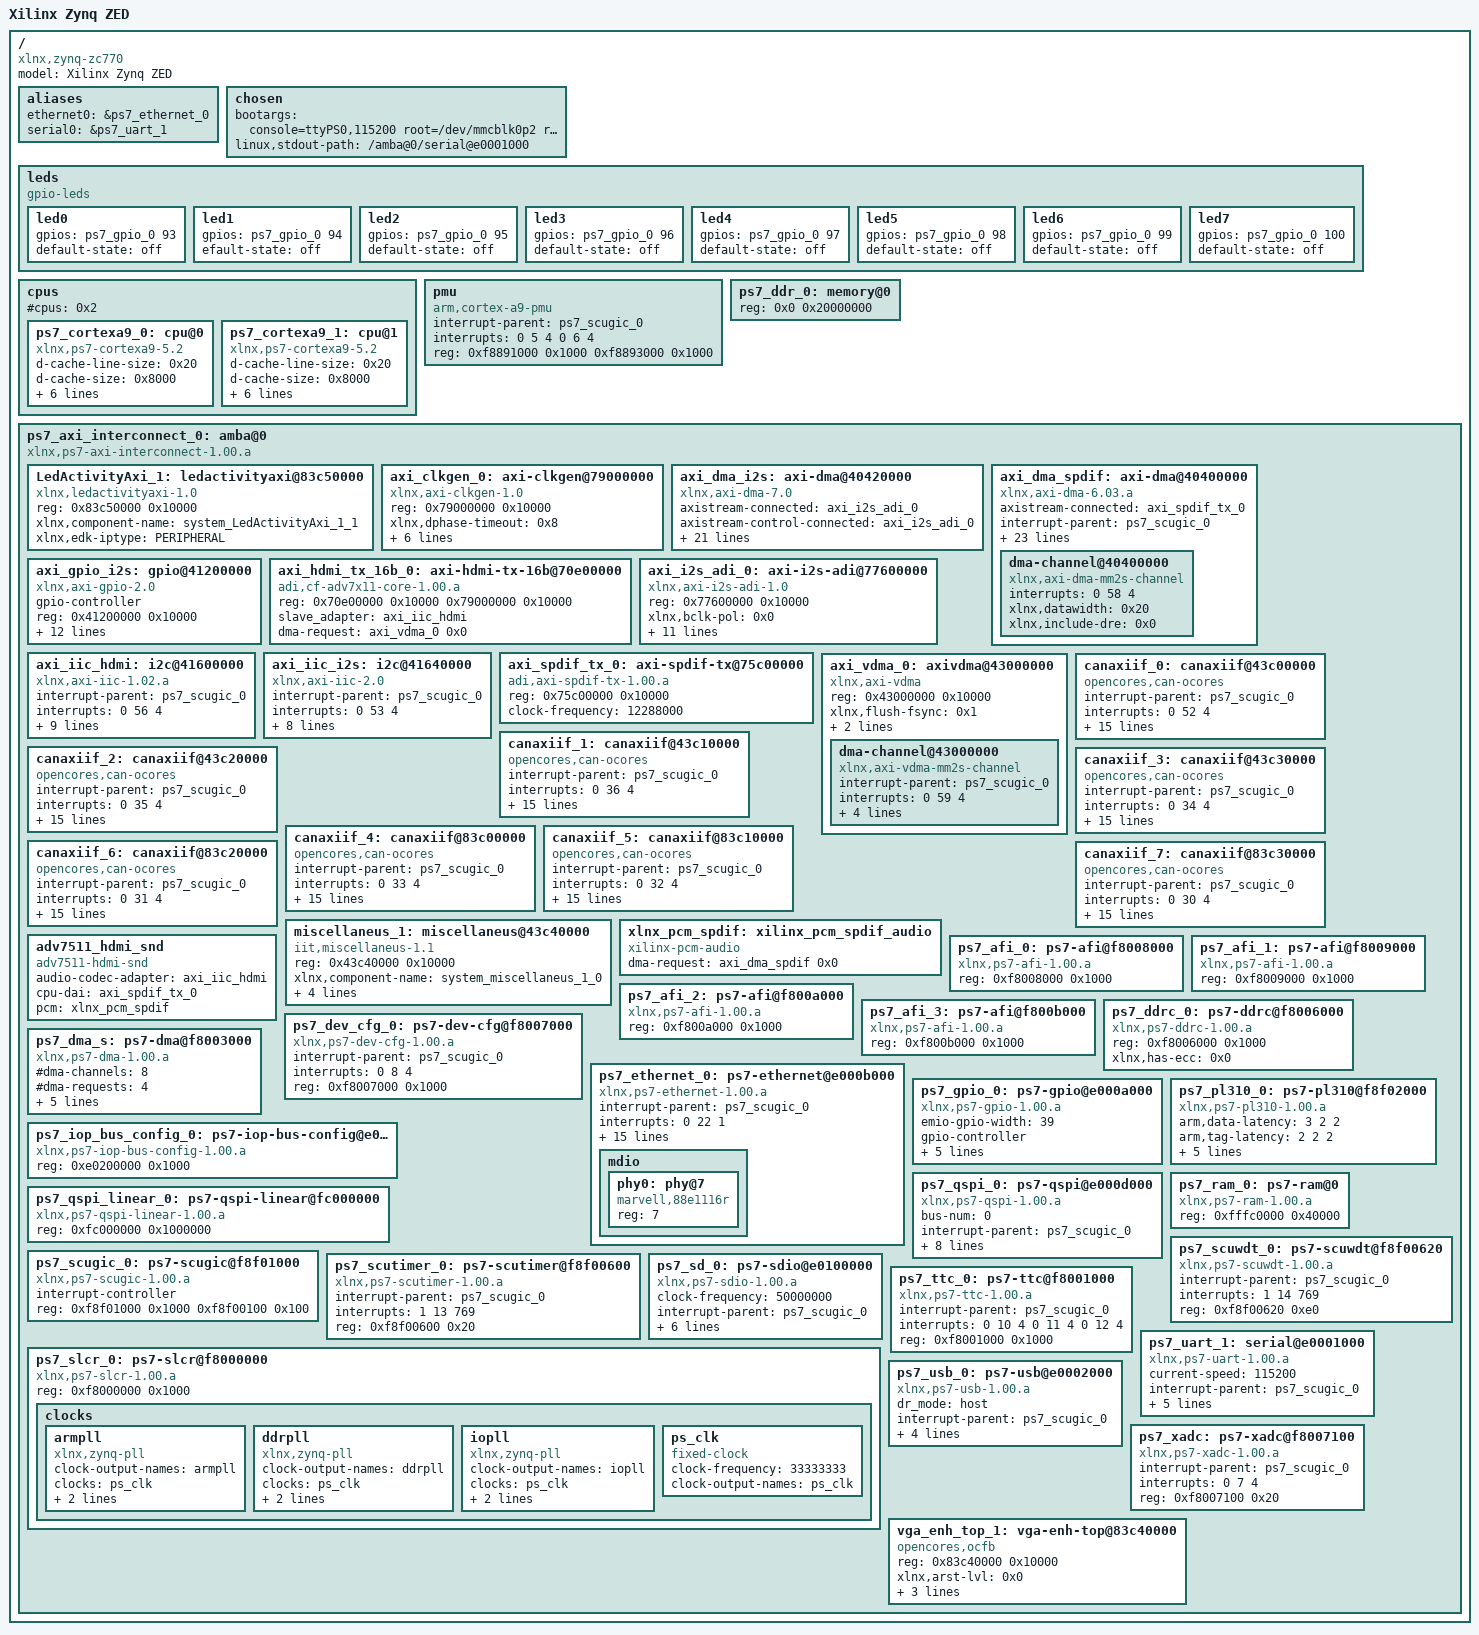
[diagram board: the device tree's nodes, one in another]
/*
 * Device Tree Generator version: 1.1
 *
 * (C) Copyright 2007-2012 Xilinx, Inc.
 * (C) Copyright 2007-2012 Michal Simek
 * (C) Copyright 2007-2012 PetaLogix Qld Pty Ltd
 *
 * Michal SIMEK <monstr@monstr.eu>
 *
 * This program is free software; you can redistribute it and/or
 * modify it under the terms of the GNU General Public License as
 * published by the Free Software Foundation; either version 2 of
 * the License, or (at your option) any later version.
 *
 * This program is distributed in the hope that it will be useful,
 * but WITHOUT ANY WARRANTY; without even the implied warranty of
 * MERCHANTABILITY or FITNESS FOR A PARTICULAR PURPOSE. See the
 * GNU General Public License for more details.
 *
 * You should have received a copy of the GNU General Public License
 * along with this program; if not, write to the Free Software
 * Foundation, Inc., 59 Temple Place, Suite 330, Boston,
 * MA 02111-1307 USA
 *
 * CAUTION: This file is automatically generated by libgen.
 * Version: Xilinx EDK 2013.2 EDK_P.68d
 * Today is: Monday, the 14 of April, 2014; 10:22:48
 *
 * XPS project directory: device-tree_bsp_0
 */

/dts-v1/;
/ {
	#address-cells = <1>;
	#size-cells = <1>;
	compatible = "xlnx,zynq-zc770";
	model = "Xilinx Zynq ZED";

	aliases {
		ethernet0 = &ps7_ethernet_0;
		serial0 = &ps7_uart_1;
	} ;
	chosen {
     /* Booting from SD  */
		bootargs = "console=ttyPS0,115200 root=/dev/mmcblk0p2 rw earlyprintk rootfstype=ext4 rootwait devtmpfs.mount=1 xeno_nucleus.xenomai_gid=1002";
     
     /* Booting from USB 
		bootargs = "console=ttyPS0,115200 root=/dev/sda1 rw earlyprintk rootfstype=ext4 rootwait devtmpfs.mount=1 xeno_nucleus.xenomai_gid=1002";
	  */	
	linux,stdout-path = "/amba@0/serial@e0001000";
	} ;

    leds {
        compatible = "gpio-leds";
        led0 {
            gpios = <&ps7_gpio_0 93 0>;
            default-state = "off";
        };
        led1 {
           gpios = <&ps7_gpio_0 94 0>;
           efault-state = "off";
        };
        led2 {
           gpios = <&ps7_gpio_0 95 0>;
           default-state = "off";
        };
        led3 {
            gpios = <&ps7_gpio_0 96 0>;
            default-state = "off";
        };
        led4 {
           gpios = <&ps7_gpio_0 97 0>;
           default-state = "off";
        };
        led5 {
            gpios = <&ps7_gpio_0 98 0>;
            default-state = "off";
        };
        led6 {
           gpios = <&ps7_gpio_0 99 0>;
           default-state = "off";
        };
        led7 {
           gpios = <&ps7_gpio_0 100 0>;
           default-state = "off";
        };
    };

	cpus {
		#address-cells = <1>;
		#cpus = <0x2>;
		#size-cells = <0>;
		ps7_cortexa9_0: cpu@0 {
			compatible = "xlnx,ps7-cortexa9-5.2";
			d-cache-line-size = <0x20>;
			d-cache-size = <0x8000>;
			device_type = "cpu";
			i-cache-line-size = <0x20>;
			i-cache-size = <0x8000>;
			model = "ps7_cortexa9,5.2";
			reg = <0>;
			xlnx,cpu-1x-clk-freq-hz = <0x69f6bcb>;
			xlnx,cpu-clk-freq-hz = <0x27bc86bf>;
		} ;
		ps7_cortexa9_1: cpu@1 {
			compatible = "xlnx,ps7-cortexa9-5.2";
			d-cache-line-size = <0x20>;
			d-cache-size = <0x8000>;
			device_type = "cpu";
			i-cache-line-size = <0x20>;
			i-cache-size = <0x8000>;
			model = "ps7_cortexa9,5.2";
			reg = <1>;
			xlnx,cpu-1x-clk-freq-hz = <0x69f6bcb>;
			xlnx,cpu-clk-freq-hz = <0x27bc86bf>;
		} ;
	} ;
	pmu {
		compatible = "arm,cortex-a9-pmu";
		interrupt-parent = <&ps7_scugic_0>;
		interrupts = < 0 5 4 0 6 4 >;
		reg = < 0xf8891000 0x1000 0xf8893000 0x1000 >;
	} ;
	ps7_ddr_0: memory@0 {
		device_type = "memory";
		reg = < 0x0 0x20000000 >;
	} ;
	ps7_axi_interconnect_0: amba@0 {
		#address-cells = <1>;
		#size-cells = <1>;
		compatible = "xlnx,ps7-axi-interconnect-1.00.a", "simple-bus";
		ranges ;
		LedActivityAxi_1: ledactivityaxi@83c50000 {
			compatible = "xlnx,ledactivityaxi-1.0";
			reg = < 0x83c50000 0x10000 >;
			xlnx,component-name = "system_LedActivityAxi_1_1";
			xlnx,edk-iptype = "PERIPHERAL";
		} ;
		axi_clkgen_0: axi-clkgen@79000000 {
			compatible = "xlnx,axi-clkgen-1.0";
			reg = < 0x79000000 0x10000 >;
			xlnx,dphase-timeout = <0x8>;
			xlnx,num-mem = <0x1>;
			xlnx,num-reg = <0x1>;
			xlnx,s-axi-min-size = <0x1ff>;
			xlnx,slv-awidth = <0x20>;
			xlnx,slv-dwidth = <0x20>;
			xlnx,use-wstrb = <0x0>;
		} ;
		axi_dma_i2s: axi-dma@40420000 {
			axistream-connected = <&axi_i2s_adi_0>;
			axistream-control-connected = <&axi_i2s_adi_0>;
			compatible = "xlnx,axi-dma-7.0", "xlnx,axi-dma-1.00.a";
			interrupt-parent = <&ps7_scugic_0>;
			interrupts = < 0 55 4 0 54 4 >;
			reg = < 0x40420000 0x10000 >;
			xlnx,dlytmr-resolution = <0x7d>;
			xlnx,enable-multi-channel = <0x0>;
			xlnx,include-mm2s = <0x1>;
			xlnx,include-mm2s-dre = <0x0>;
			xlnx,include-mm2s-sf = <0x1>;
			xlnx,include-s2mm = <0x1>;
			xlnx,include-s2mm-dre = <0x0>;
			xlnx,include-s2mm-sf = <0x1>;
			xlnx,include-sg = <0x1>;
			xlnx,mm2s-burst-size = <0x10>;
			xlnx,num-mm2s-channels = <0x1>;
			xlnx,num-s2mm-channels = <0x1>;
			xlnx,prmry-is-aclk-async = <0x0>;
			xlnx,s2mm-burst-size = <0x10>;
			xlnx,sg-include-desc-queue = <0x1>;
			xlnx,sg-include-stscntrl-strm = <0x0>;
			xlnx,sg-length-width = <0xe>;
			xlnx,sg-use-stsapp-length = <0x0>;
		} ;
		axi_dma_spdif: axi-dma@40400000 {
			#address-cells = <1>;
			#size-cells = <1>;
			#dma-cells = <1>;
			axistream-connected = <&axi_spdif_tx_0>;
			compatible = "xlnx,axi-dma-6.03.a", "xlnx,axi-dma-1.00.a", "xlnx,axi-dma";
			interrupt-parent = <&ps7_scugic_0>;
			interrupts = < 0 58 4 >;
			reg = < 0x40400000 0x10000 >;
			xlnx,sg-include-stscntrl-strm = <0x0>;
			xlnx,dlytmr-resolution = <0x7d>;
			xlnx,enable-multi-channel = <0x0>;
			xlnx,family = "zynq";
			xlnx,generic = <0x0>;
			xlnx,include-mm2s = <0x1>;
			xlnx,include-mm2s-dre = <0x0>;
			xlnx,include-mm2s-sf = <0x1>;
			xlnx,include-s2mm = <0x0>;
			xlnx,include-s2mm-dre = <0x0>;
			xlnx,include-s2mm-sf = <0x1>;
			xlnx,include-sg = <0x1>;
			xlnx,instance = "axi_dma_spdif";
			xlnx,mm2s-burst-size = <0x10>;
			xlnx,num-mm2s-channels = <0x1>;
			xlnx,num-s2mm-channels = <0x1>;
			xlnx,prmry-is-aclk-async = <0x0>;
			xlnx,s2mm-burst-size = <0x10>;
			xlnx,sg-include-desc-queue = <0x0>;
			xlnx,sg-length-width = <0x14>;  
			xlnx,sg-use-stsapp-length = <0x1>;

			dma-channel@40400000 {
				compatible = "xlnx,axi-dma-mm2s-channel";
				interrupts = < 0 58 4 >;
				xlnx,datawidth = <0x20>;
				xlnx,include-dre = <0x0>;
			};
		} ;
		axi_gpio_i2s: gpio@41200000 {
			#gpio-cells = <2>;
			compatible = "xlnx,axi-gpio-2.0", "xlnx,xps-gpio-1.00.a";
			gpio-controller ;
			reg = < 0x41200000 0x10000 >;
			xlnx,all-inputs = <0x0>;
			xlnx,all-inputs-2 = <0x0>;
			xlnx,all-outputs = <0x0>;
			xlnx,all-outputs-2 = <0x0>;
			xlnx,dout-default = <0x0>;
			xlnx,dout-default-2 = <0x0>;
			xlnx,gpio-width = <0x2>;
			xlnx,gpio2-width = <0x20>;
			xlnx,interrupt-present = <0x0>;
			xlnx,is-dual = <0x0>;
			xlnx,tri-default = <0xffffffff>;
			xlnx,tri-default-2 = <0xffffffff>;
		} ;
		axi_hdmi_tx_16b_0: axi-hdmi-tx-16b@70e00000 {
			compatible = "adi,cf-adv7x11-core-1.00.a";
			reg = < 0x70e00000 0x10000 0x79000000 0x10000 >;
			slave_adapter = <&axi_iic_hdmi>;
			dma-request = <&axi_vdma_0 0x0>;
		} ;
		axi_i2s_adi_0: axi-i2s-adi@77600000 {
			compatible = "xlnx,axi-i2s-adi-1.0";
			reg = < 0x77600000 0x10000 >;
			xlnx,bclk-pol = <0x0>;
			xlnx,data-width = <0x18>;
			xlnx,dphase-timeout = <0x8>;
			xlnx,frm-sync = <0x0>;
			xlnx,lrclk-pol = <0x0>;
			xlnx,msb-pos = <0x0>;
			xlnx,num-mem = <0x1>;
			xlnx,num-reg = <0x1>;
			xlnx,s-axi-min-size = <0x1ff>;
			xlnx,slv-awidth = <0x20>;
			xlnx,slv-dwidth = <0x20>;
			xlnx,use-wstrb = <0x0>;
		} ;
		axi_iic_hdmi: i2c@41600000 {
			compatible = "xlnx,axi-iic-1.02.a", "xlnx,xps-iic-2.00.a";
			interrupt-parent = <&ps7_scugic_0>;
			interrupts = < 0 56 4 >;
			reg = < 0x41600000 0x10000 >;
			xlnx,family = "zynq";
			xlnx,gpo-width = <0x1>;
			xlnx,iic-freq = <0x186a0>;
			xlnx,instance = "axi_iic_hdmi";
			xlnx,scl-inertial-delay = <0x0>;
			xlnx,sda-inertial-delay = <0x0>;
			xlnx,sda-level = <0x1>;
			xlnx,ten-bit-adr = <0x0>;
		} ;
		axi_iic_i2s: i2c@41640000 {
			compatible = "xlnx,axi-iic-2.0", "xlnx,xps-iic-2.00.a";
			interrupt-parent = <&ps7_scugic_0>;
			interrupts = < 0 53 4 >;
			reg = < 0x41640000 0x10000 >;
			xlnx,gpo-width = <0x1>;
			xlnx,iic-freq = <0x186a0>;
			xlnx,scl-inertial-delay = <0x0>;
			xlnx,sda-inertial-delay = <0x0>;
			xlnx,sda-level = <0x1>;
			xlnx,smbus-pmbus-host = <0x0>;
			xlnx,ten-bit-adr = <0x0>;
		} ;
		axi_spdif_tx_0: axi-spdif-tx@75c00000 {
			compatible = "adi,axi-spdif-tx-1.00.a";
			reg = < 0x75c00000 0x10000 >;
			clock-frequency = <12288000>;
		} ;
		/* ADV7511 Part (HDMI SPDIF Sound Supported) */
		axi_vdma_0: axivdma@43000000 {
			#address-cells = <1>;
			#size-cells = <1>;
			#dma-cells = <1>;
			compatible = "xlnx,axi-vdma";
			ranges = < 0x43000000 0x43000000 0x10000 >;
			reg = < 0x43000000 0x10000 >;
			xlnx,flush-fsync = <0x1>;
			xlnx,include-sg = <0x0>;
			xlnx,num-fstores = <0x3>;
			dma-channel@43000000 {
				compatible = "xlnx,axi-vdma-mm2s-channel";
				interrupt-parent = <&ps7_scugic_0>;
				interrupts = < 0 59 4 >;
				xlnx,datawidth = <0x40>;
				xlnx,device-id = <0x0>;
				xlnx,genlock-mode = <0x0>;
				xlnx,include-dre = <0x0>;
			} ;
		} ;
		
		canaxiif_0: canaxiif@43c00000 {
			compatible = "opencores,can-ocores";
			interrupt-parent = <&ps7_scugic_0>;
			interrupts = < 0 52 4 >;
			reg = < 0x43c00000 0x10000 >;
			xlnx,component-name = "system_canaxiif_1_1";
			xlnx,dphase-timeout = <0x30>;
			xlnx,edk-iptype = "PERIPHERAL";
			xlnx,family = "virtex6";
			xlnx,interrupt-present = <0x1>;
			xlnx,num-mem = <0x1>;
			xlnx,num-reg = <0x1>;
			xlnx,s-axi-min-size = <0x1ff>;
			xlnx,slv-awidth = <0x20>;
			xlnx,slv-dwidth = <0x20>;
			xlnx,use-wstrb = <0x0>;
            iit_ledctrl = <0x83c50000>;
            iit_resetctrl = <0x43c40000>;
            iit_ordnum = <0x0>;
		} ;
		canaxiif_1: canaxiif@43c10000 {
			compatible = "opencores,can-ocores";
			interrupt-parent = <&ps7_scugic_0>;
			interrupts = < 0 36 4 >;
			reg = < 0x43c10000 0x10000 >;
			xlnx,component-name = "system_canaxiif_0_4";
			xlnx,dphase-timeout = <0x30>;
			xlnx,edk-iptype = "PERIPHERAL";
			xlnx,family = "virtex6";
			xlnx,interrupt-present = <0x1>;
			xlnx,num-mem = <0x1>;
			xlnx,num-reg = <0x1>;
			xlnx,s-axi-min-size = <0x1ff>;
			xlnx,slv-awidth = <0x20>;
			xlnx,slv-dwidth = <0x20>;
			xlnx,use-wstrb = <0x0>;
            iit_ledctrl = <0x83c50000>;
            iit_resetctrl = <0x43c40000>;
            iit_ordnum = <0x1>;
		} ;
		canaxiif_2: canaxiif@43c20000 {
			compatible = "opencores,can-ocores";
			interrupt-parent = <&ps7_scugic_0>;
			interrupts = < 0 35 4 >;
			reg = < 0x43c20000 0x10000 >;
			xlnx,component-name = "system_canaxiif_1_5";
			xlnx,dphase-timeout = <0x30>;
			xlnx,edk-iptype = "PERIPHERAL";
			xlnx,family = "virtex6";
			xlnx,interrupt-present = <0x1>;
			xlnx,num-mem = <0x1>;
			xlnx,num-reg = <0x1>;
			xlnx,s-axi-min-size = <0x1ff>;
			xlnx,slv-awidth = <0x20>;
			xlnx,slv-dwidth = <0x20>;
			xlnx,use-wstrb = <0x0>;
            iit_ledctrl = <0x83c50000>;
            iit_resetctrl = <0x43c40000>;
            iit_ordnum = <0x2>;
		} ;
		canaxiif_3: canaxiif@43c30000 {
			compatible = "opencores,can-ocores";
			interrupt-parent = <&ps7_scugic_0>;
			interrupts = < 0 34 4 >;
			reg = < 0x43c30000 0x10000 >;
			xlnx,component-name = "system_canaxiif_2_6";
			xlnx,dphase-timeout = <0x30>;
			xlnx,edk-iptype = "PERIPHERAL";
			xlnx,family = "virtex6";
			xlnx,interrupt-present = <0x1>;
			xlnx,num-mem = <0x1>;
			xlnx,num-reg = <0x1>;
			xlnx,s-axi-min-size = <0x1ff>;
			xlnx,slv-awidth = <0x20>;
			xlnx,slv-dwidth = <0x20>;
			xlnx,use-wstrb = <0x0>;
            iit_ledctrl = <0x83c50000>;
            iit_resetctrl = <0x43c40000>;
            iit_ordnum = <0x3>;
		} ;
		canaxiif_4: canaxiif@83c00000 {
			compatible = "opencores,can-ocores";
			interrupt-parent = <&ps7_scugic_0>;
			interrupts = < 0 33 4 >;
			reg = < 0x83c00000 0x10000 >;
			xlnx,component-name = "system_canaxiif_3_7";
			xlnx,dphase-timeout = <0x30>;
			xlnx,edk-iptype = "PERIPHERAL";
			xlnx,family = "virtex6";
			xlnx,interrupt-present = <0x1>;
			xlnx,num-mem = <0x1>;
			xlnx,num-reg = <0x1>;
			xlnx,s-axi-min-size = <0x1ff>;
			xlnx,slv-awidth = <0x20>;
			xlnx,slv-dwidth = <0x20>;
			xlnx,use-wstrb = <0x0>;
            iit_ledctrl = <0x83c50000>;
            iit_resetctrl = <0x43c40000>;
            iit_ordnum = <0x4>;
		} ;
		canaxiif_5: canaxiif@83c10000 {
			compatible = "opencores,can-ocores";
			interrupt-parent = <&ps7_scugic_0>;
			interrupts = < 0 32 4 >;
			reg = < 0x83c10000 0x10000 >;
			xlnx,component-name = "system_canaxiif_4_8";
			xlnx,dphase-timeout = <0x30>;
			xlnx,edk-iptype = "PERIPHERAL";
			xlnx,family = "virtex6";
			xlnx,interrupt-present = <0x1>;
			xlnx,num-mem = <0x1>;
			xlnx,num-reg = <0x1>;
			xlnx,s-axi-min-size = <0x1ff>;
			xlnx,slv-awidth = <0x20>;
			xlnx,slv-dwidth = <0x20>;
			xlnx,use-wstrb = <0x0>;
            iit_ledctrl = <0x83c50000>;
            iit_resetctrl = <0x43c40000>;
            iit_ordnum = <0x5>;
		} ;
		canaxiif_6: canaxiif@83c20000 {
			compatible = "opencores,can-ocores";
			interrupt-parent = <&ps7_scugic_0>;
			interrupts = < 0 31 4 >;
			reg = < 0x83c20000 0x10000 >;
			xlnx,component-name = "system_canaxiif_5_9";
			xlnx,dphase-timeout = <0x30>;
			xlnx,edk-iptype = "PERIPHERAL";
			xlnx,family = "virtex6";
			xlnx,interrupt-present = <0x1>;
			xlnx,num-mem = <0x1>;
			xlnx,num-reg = <0x1>;
			xlnx,s-axi-min-size = <0x1ff>;
			xlnx,slv-awidth = <0x20>;
			xlnx,slv-dwidth = <0x20>;
			xlnx,use-wstrb = <0x0>;
            iit_ledctrl = <0x83c50000>;
            iit_resetctrl = <0x43c40000>;
            iit_ordnum = <0x6>;
		} ;
		canaxiif_7: canaxiif@83c30000 {
			compatible = "opencores,can-ocores";
			interrupt-parent = <&ps7_scugic_0>;
			interrupts = < 0 30 4 >;
			reg = < 0x83c30000 0x10000 >;
			xlnx,component-name = "system_canaxiif_6_10";
			xlnx,dphase-timeout = <0x30>;
			xlnx,edk-iptype = "PERIPHERAL";
			xlnx,family = "virtex6";
			xlnx,interrupt-present = <0x1>;
			xlnx,num-mem = <0x1>;
			xlnx,num-reg = <0x1>;
			xlnx,s-axi-min-size = <0x1ff>;
			xlnx,slv-awidth = <0x20>;
			xlnx,slv-dwidth = <0x20>;
			xlnx,use-wstrb = <0x0>;
            iit_ledctrl = <0x83c50000>;
            iit_resetctrl = <0x43c40000>;
            iit_ordnum = <0x7>;
		} ;
		miscellaneus_1: miscellaneus@43c40000 {
			compatible = "iit,miscellaneus-1.1";
			reg = < 0x43c40000 0x10000 >;
			xlnx,component-name = "system_miscellaneus_1_0";
			xlnx,edk-iptype = "PERIPHERAL";
			xlnx,id-version = "WR";
			xlnx,major = <0x1>;
			xlnx,minor = <0x1>;
		} ;
        xlnx_pcm_spdif: xilinx_pcm_spdif_audio {
                   compatible = "xilinx-pcm-audio";
                   dma-request = <&axi_dma_spdif 0x0>;
           };      
        adv7511_hdmi_snd {
            compatible = "adv7511-hdmi-snd";
            audio-codec-adapter = <&axi_iic_hdmi>;
            cpu-dai = <&axi_spdif_tx_0>;
            pcm = <&xlnx_pcm_spdif>;
		} ;
		ps7_afi_0: ps7-afi@f8008000 {
			compatible = "xlnx,ps7-afi-1.00.a";
			reg = < 0xf8008000 0x1000 >;
		} ;
		ps7_afi_1: ps7-afi@f8009000 {
			compatible = "xlnx,ps7-afi-1.00.a";
			reg = < 0xf8009000 0x1000 >;
		} ;
		ps7_afi_2: ps7-afi@f800a000 {
			compatible = "xlnx,ps7-afi-1.00.a";
			reg = < 0xf800a000 0x1000 >;
		} ;
		ps7_afi_3: ps7-afi@f800b000 {
			compatible = "xlnx,ps7-afi-1.00.a";
			reg = < 0xf800b000 0x1000 >;
		} ;
		ps7_ddrc_0: ps7-ddrc@f8006000 {
			compatible = "xlnx,ps7-ddrc-1.00.a", "xlnx,ps7-ddrc";
			reg = < 0xf8006000 0x1000 >;
			xlnx,has-ecc = <0x0>;
		} ;
		ps7_dev_cfg_0: ps7-dev-cfg@f8007000 {
			compatible = "xlnx,ps7-dev-cfg-1.00.a";
			interrupt-parent = <&ps7_scugic_0>;
			interrupts = < 0 8 4 >;
			reg = < 0xf8007000 0x1000 >;
		} ;
		ps7_dma_s: ps7-dma@f8003000 {
			#dma-cells = <1>;
			#dma-channels = <8>;
			#dma-requests = <4>;
			arm,primecell-periphid = <0x41330>;
			compatible = "xlnx,ps7-dma-1.00.a", "arm,primecell", "arm,pl330";
			interrupt-parent = <&ps7_scugic_0>;
			interrupts = < 0 13 4 0 14 4 0 15 4 0 16 4 0 17 4 0 40 4 0 41 4 0 42 4 0 43 4 >;
			reg = < 0xf8003000 0x1000 >;
		} ;
		ps7_ethernet_0: ps7-ethernet@e000b000 {
			#address-cells = <1>;
			#size-cells = <0>;
			compatible = "xlnx,ps7-ethernet-1.00.a";
			interrupt-parent = <&ps7_scugic_0>;
			interrupts = < 0 22 1 >;
			local-mac-address = [ 00 0a 35 00 00 00 ];
			phy-handle = <&phy0>;
			phy-mode = "rgmii-id";
			reg = < 0xe000b000 0x1000 >;
			xlnx,enet-clk-freq-hz = <0x7735940>;
			xlnx,enet-reset = "";
			xlnx,enet-slcr-1000mbps-div0 = <0x8>;
			xlnx,enet-slcr-1000mbps-div1 = <0x1>;
			xlnx,enet-slcr-100mbps-div0 = <0x8>;
			xlnx,enet-slcr-100mbps-div1 = <0x5>;
			xlnx,enet-slcr-10mbps-div0 = <0x8>;
			xlnx,enet-slcr-10mbps-div1 = <0x32>;
			xlnx,eth-mode = <0x1>;
			xlnx,has-mdio = <0x1>;
			xlnx,ptp-enet-clock = <111111115>;
			mdio {
				#address-cells = <1>;
				#size-cells = <0>;
				phy0: phy@7 {
					compatible = "marvell,88e1116r";
					device_type = "ethernet-phy";
					reg = <7>;
				} ;
			} ;
		} ;
		ps7_gpio_0: ps7-gpio@e000a000 {
			#gpio-cells = <2>;
			compatible = "xlnx,ps7-gpio-1.00.a";
			emio-gpio-width = <39>;
			gpio-controller ;
			gpio-mask-high = <0x0>;
			gpio-mask-low = <0x5600>;
			interrupt-parent = <&ps7_scugic_0>;
			interrupts = < 0 20 4 >;
			reg = < 0xe000a000 0x1000 >;
		} ;
		ps7_iop_bus_config_0: ps7-iop-bus-config@e0200000 {
			compatible = "xlnx,ps7-iop-bus-config-1.00.a";
			reg = < 0xe0200000 0x1000 >;
		} ;
		ps7_pl310_0: ps7-pl310@f8f02000 {
			arm,data-latency = < 3 2 2 >;
			arm,tag-latency = < 2 2 2 >;
			cache-level = < 2 >;
			cache-unified ;
			compatible = "xlnx,ps7-pl310-1.00.a", "arm,pl310-cache";
			interrupt-parent = <&ps7_scugic_0>;
			interrupts = < 0 2 4 >;
			reg = < 0xf8f02000 0x1000 >;
		} ;
		ps7_qspi_0: ps7-qspi@e000d000 {
			bus-num = <0>;
			compatible = "xlnx,ps7-qspi-1.00.a";
			interrupt-parent = <&ps7_scugic_0>;
			interrupts = < 0 19 4 >;
			is-dual = <0>;
			num-chip-select = <1>;
			reg = < 0xe000d000 0x1000 >;
			speed-hz = <190476196>;
			xlnx,fb-clk = <0x1>;
			xlnx,qspi-clk-freq-hz = <0xb5a6fa4>;
			xlnx,qspi-mode = <0x0>;
		} ;
		ps7_qspi_linear_0: ps7-qspi-linear@fc000000 {
			compatible = "xlnx,ps7-qspi-linear-1.00.a";
			reg = < 0xfc000000 0x1000000 >;
		} ;
		ps7_ram_0: ps7-ram@0 {
			compatible = "xlnx,ps7-ram-1.00.a", "xlnx,ps7-ocm";
			reg = < 0xfffc0000 0x40000 >;
		} ;
		ps7_scugic_0: ps7-scugic@f8f01000 {
			#address-cells = < 2 >;
			#interrupt-cells = < 3 >;
			#size-cells = < 1 >;
			compatible = "xlnx,ps7-scugic-1.00.a", "arm,cortex-a9-gic", "arm,gic";
			interrupt-controller ;
			linux,phandle = < 0x1 >;
			phandle = < 0x1 >;
			reg = < 0xf8f01000 0x1000 0xf8f00100 0x100 >;
		} ;
		ps7_scutimer_0: ps7-scutimer@f8f00600 {
			compatible = "xlnx,ps7-scutimer-1.00.a", "arm,cortex-a9-twd-timer";
			interrupt-parent = <&ps7_scugic_0>;
			interrupts = < 1 13 769 >;
			reg = < 0xf8f00600 0x20 >;
		} ;
		ps7_scuwdt_0: ps7-scuwdt@f8f00620 {
			compatible = "xlnx,ps7-scuwdt-1.00.a";
			device_type = "watchdog";
			interrupt-parent = <&ps7_scugic_0>;
			interrupts = < 1 14 769 >;
			reg = < 0xf8f00620 0xe0 >;
		} ;
		ps7_sd_0: ps7-sdio@e0100000 {
			clock-frequency = <50000000>;
			compatible = "xlnx,ps7-sdio-1.00.a", "generic-sdhci";
			interrupt-parent = <&ps7_scugic_0>;
			interrupts = < 0 24 4 >;
			reg = < 0xe0100000 0x1000 >;
			xlnx,has-cd = <0x1>;
			xlnx,has-power = <0x0>;
			xlnx,has-wp = <0x1>;
			xlnx,sdio-clk-freq-hz = <0x2faf080>;
		} ;
		ps7_slcr_0: ps7-slcr@f8000000 {
			compatible = "xlnx,ps7-slcr-1.00.a", "xlnx,zynq-slcr";
			reg = < 0xf8000000 0x1000 >;
			clocks {
				#address-cells = <1>;
				#size-cells = <0>;
				armpll: armpll {
					#clock-cells = <0>;
					clock-output-names = "armpll";
					clocks = <&ps_clk>;
					compatible = "xlnx,zynq-pll";
					lockbit = <0>;
					reg = < 0x100 0x110 0x10c >;
				} ;
				ddrpll: ddrpll {
					#clock-cells = <0>;
					clock-output-names = "ddrpll";
					clocks = <&ps_clk>;
					compatible = "xlnx,zynq-pll";
					lockbit = <1>;
					reg = < 0x104 0x114 0x10c >;
				} ;
				iopll: iopll {
					#clock-cells = <0>;
					clock-output-names = "iopll";
					clocks = <&ps_clk>;
					compatible = "xlnx,zynq-pll";
					lockbit = <2>;
					reg = < 0x108 0x118 0x10c >;
				} ;
				ps_clk: ps_clk {
					#clock-cells = <0>;
					clock-frequency = <33333333>;
					clock-output-names = "ps_clk";
					compatible = "fixed-clock";
				} ;
			} ;
		} ;
		ps7_ttc_0: ps7-ttc@f8001000 {
			compatible = "xlnx,ps7-ttc-1.00.a";
			interrupt-parent = <&ps7_scugic_0>;
			interrupts = < 0 10 4 0 11 4 0 12 4 >;
			reg = < 0xf8001000 0x1000 >;
		} ;
		ps7_uart_1: serial@e0001000 {
			compatible = "xlnx,ps7-uart-1.00.a", "xlnx,xuartps";
			current-speed = <115200>;
			device_type = "serial";
			interrupt-parent = <&ps7_scugic_0>;
			interrupts = < 0 50 4 >;
			port-number = <0>;
			reg = < 0xe0001000 0x1000 >;
			xlnx,has-modem = <0x0>;
			xlnx,uart-clk-freq-hz = <0x2faf080>;
		} ;
		ps7_usb_0: ps7-usb@e0002000 {
			compatible = "xlnx,ps7-usb-1.00.a";
			dr_mode = "host";
			interrupt-parent = <&ps7_scugic_0>;
			interrupts = < 0 21 4 >;
			phy_type = "ulpi";
			reg = < 0xe0002000 0x1000 >;
			xlnx,usb-reset = "";
		} ;
		ps7_xadc: ps7-xadc@f8007100 {
			compatible = "xlnx,ps7-xadc-1.00.a";
			interrupt-parent = <&ps7_scugic_0>;
			interrupts = < 0 7 4 >;
			reg = < 0xf8007100 0x20 >;
		} ;
		vga_enh_top_1: vga-enh-top@83c40000 {
			compatible = "opencores,ocfb";
			reg = < 0x83c40000 0x10000 >;
			xlnx,arst-lvl = <0x0>;
			xlnx,component-name = "system_vga_enh_top_1_0";
			xlnx,edk-iptype = "PERIPHERAL";
			xlnx,line-fifo-awidth = <0x8>;
		} ;
	} ;
} ;
